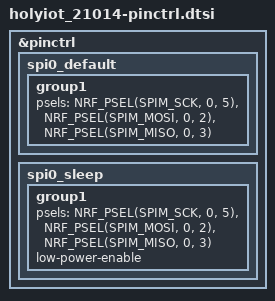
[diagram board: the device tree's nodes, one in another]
/*
 * SPDX-FileCopyrightText: Copyright (c) 2025 Clunky Machines
 * SPDX-License-Identifier: Apache-2.0
 */

&pinctrl {
	spi0_default: spi0_default {
		group1 {
			psels = <NRF_PSEL(SPIM_SCK, 0, 5)>,
				<NRF_PSEL(SPIM_MOSI, 0, 2)>,
				<NRF_PSEL(SPIM_MISO, 0, 3)>;
		};
	};

	spi0_sleep: spi0_sleep {
		group1 {
			psels = <NRF_PSEL(SPIM_SCK, 0, 5)>,
				<NRF_PSEL(SPIM_MOSI, 0, 2)>,
				<NRF_PSEL(SPIM_MISO, 0, 3)>;
			low-power-enable;
		};
	};
};
